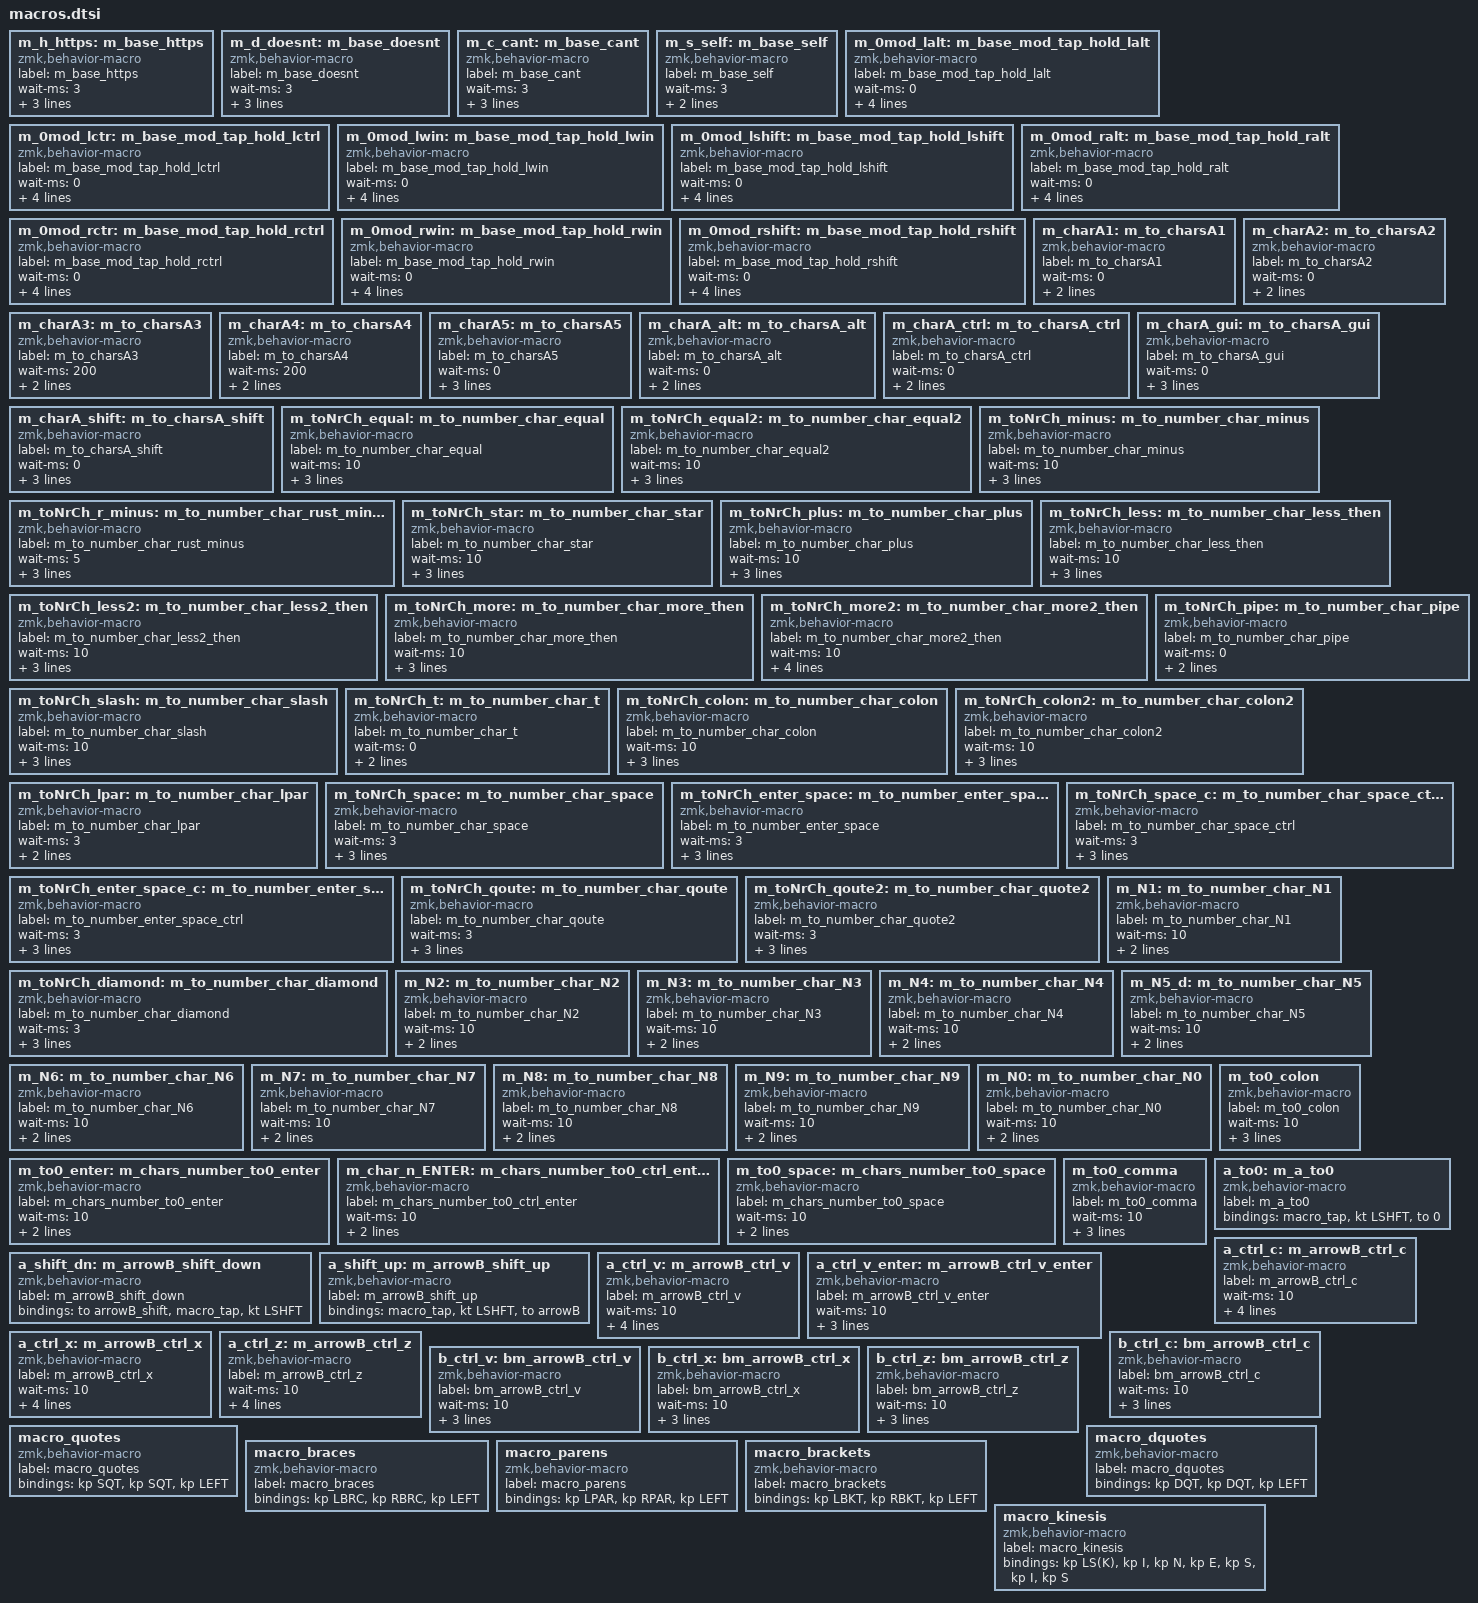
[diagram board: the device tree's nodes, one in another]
// --------------------------------------------------------


// --------------------------------------------------------

// string: 'https://'
m_h_https: m_base_https  {
            label = "m_base_https";
            compatible = "zmk,behavior-macro";
            #binding-cells = <0>;
            wait-ms = <3>;
            tap-ms = <8>;
            bindings
              = <&macro_tap &kp H &kp T &kp T &kp P &kp S &kp COLON &kp SLASH &kp SLASH>;
      };

m_d_doesnt: m_base_doesnt  {
            label = "m_base_doesnt";
            compatible = "zmk,behavior-macro";
            #binding-cells = <0>;
            wait-ms = <3>;
            tap-ms = <8>;
            bindings
              = <&macro_tap &kp D &kp O &kp E &kp S &kp N &kp SINGLE_QUOTE &kp T>;
      };

m_c_cant: m_base_cant  {
            label = "m_base_cant";
            compatible = "zmk,behavior-macro";
            #binding-cells = <0>;
            wait-ms = <3>;
            tap-ms = <8>;
            bindings
              = <&macro_tap &kp C &kp A &kp N &kp SINGLE_QUOTE &kp T>;
      };

// self
m_s_self: m_base_self  {
            label = "m_base_self";
            compatible = "zmk,behavior-macro";
            #binding-cells = <0>;
            wait-ms = <3>;
            tap-ms = <8>;
            bindings
              = <&macro_tap &kp S &kp E &kp L &kp F>;
              //= <&macro_tap &kp S &kp E &kp L &kp F &kp DOT>;
      };


// --------------------------------------------------------

m_0mod_lalt: m_base_mod_tap_hold_lalt  {
            label = "m_base_mod_tap_hold_lalt";
            compatible = "zmk,behavior-macro";
            #binding-cells = <0>;
            wait-ms = <0>;
            tap-ms = <0>;
            bindings
              = <&macro_press &mo base_mod &kp LALT>
              , <&macro_pause_for_release>
              , <&macro_release &mo base_mod &kp LALT>;
      };

m_0mod_lctr: m_base_mod_tap_hold_lctrl  {
            label = "m_base_mod_tap_hold_lctrl";
            compatible = "zmk,behavior-macro";
            #binding-cells = <0>;
            wait-ms = <0>;
            tap-ms = <0>;
            bindings
              = <&macro_press &mo base_mod &kp LCTRL>
              , <&macro_pause_for_release>
              , <&macro_release &mo base_mod &kp LCTRL>;
      };

m_0mod_lwin: m_base_mod_tap_hold_lwin  {
            label = "m_base_mod_tap_hold_lwin";
            compatible = "zmk,behavior-macro";
            #binding-cells = <0>;
            wait-ms = <0>;
            tap-ms = <0>;
            bindings
              = <&macro_press &mo base_mod &kp LWIN>
              , <&macro_pause_for_release>
              , <&macro_release &mo base_mod &kp LWIN>;
      };

m_0mod_lshift: m_base_mod_tap_hold_lshift  {
            label = "m_base_mod_tap_hold_lshift";
            compatible = "zmk,behavior-macro";
            #binding-cells = <0>;
            wait-ms = <0>;
            tap-ms = <0>;
            bindings
              = <&macro_press &mo base_mod &kp LSHIFT>
              , <&macro_pause_for_release>
              , <&macro_release &mo base_mod &kp LSHIFT>;
      };

// ------- 

m_0mod_ralt: m_base_mod_tap_hold_ralt  {
            label = "m_base_mod_tap_hold_ralt";
            compatible = "zmk,behavior-macro";
            #binding-cells = <0>;
            wait-ms = <0>;
            tap-ms = <0>;
            bindings
              = <&macro_press &mo base_mod &kp RALT>
              , <&macro_pause_for_release>
              , <&macro_release &mo base_mod &kp RALT>;
      };

m_0mod_rctr: m_base_mod_tap_hold_rctrl  {
            label = "m_base_mod_tap_hold_rctrl";
            compatible = "zmk,behavior-macro";
            #binding-cells = <0>;
            wait-ms = <0>;
            tap-ms = <0>;
            bindings
              = <&macro_press &mo base_mod &kp RCTRL>
              , <&macro_pause_for_release>
              , <&macro_release &mo base_mod &kp RCTRL>;
      };

m_0mod_rwin: m_base_mod_tap_hold_rwin  {
            label = "m_base_mod_tap_hold_rwin";
            compatible = "zmk,behavior-macro";
            #binding-cells = <0>;
            wait-ms = <0>;
            tap-ms = <0>;
            bindings
              = <&macro_press &mo base_mod &kp RWIN>
              , <&macro_pause_for_release>
              , <&macro_release &mo base_mod &kp RWIN>;
      };

m_0mod_rshift: m_base_mod_tap_hold_rshift  {
            label = "m_base_mod_tap_hold_rshift";
            compatible = "zmk,behavior-macro";
            #binding-cells = <0>;
            wait-ms = <0>;
            tap-ms = <0>;
            bindings
              = <&macro_press &mo base_mod &kp RSHIFT>
              , <&macro_pause_for_release>
              , <&macro_release &mo base_mod &kp RSHIFT>;
      };


// --------------------------------------------------------

m_charA1: m_to_charsA1 {
            label = "m_to_charsA1";
            compatible = "zmk,behavior-macro";
            #binding-cells = <0>;
            wait-ms = <0>;
            tap-ms = <0>;
            bindings
                = <&macro_tap &skq LALT>
                ;
      };

m_charA2: m_to_charsA2 {
            label = "m_to_charsA2";
            compatible = "zmk,behavior-macro";
            #binding-cells = <0>;
            wait-ms = <0>;
            tap-ms = <0>;
            bindings
                = <&macro_tap &sk LALT>
                ;
      };

m_charA3: m_to_charsA3 {
            label = "m_to_charsA3";
            compatible = "zmk,behavior-macro";
            #binding-cells = <0>;
            wait-ms = <200>;
            tap-ms = <200>;       
            bindings
                = <&macro_tap &sk LALT>
                ;
      };

m_charA4: m_to_charsA4 {
            label = "m_to_charsA4";
            compatible = "zmk,behavior-macro";
            #binding-cells = <0>;
            wait-ms = <200>;
            tap-ms = <200>;
            bindings
                = <&macro_tap &skq LALT>
                ;
      };

m_charA5: m_to_charsA5 {
            label = "m_to_charsA5";
            compatible = "zmk,behavior-macro";
            #binding-cells = <0>;
            wait-ms = <0>;
            tap-ms = <0>;
            bindings
                = <&macro_tap &sl1 charsA &sk1 LALT &sl1 charsA>
                ;
      };
                //= <&macro_tap &sk1 LALT &sl1 charsA>
                //, <&macro_tap &sl1 charsA>

m_charA_alt: m_to_charsA_alt {
            label = "m_to_charsA_alt";
            compatible = "zmk,behavior-macro";
            #binding-cells = <0>;
            wait-ms = <0>;
            tap-ms = <0>;
            bindings
                = <&to 0>
                , <&macro_tap &skq LALT>
                , <&sl charsA>
                ;
      };

m_charA_ctrl: m_to_charsA_ctrl {
            label = "m_to_charsA_ctrl";
            compatible = "zmk,behavior-macro";
            #binding-cells = <0>;
            wait-ms = <0>;
            tap-ms = <0>;
            bindings
                = <&macro_tap &sk LCTRL>
                , <&sl charsA>
                ;
      };

m_charA_gui: m_to_charsA_gui {
            label = "m_to_charsA_gui";
            compatible = "zmk,behavior-macro";
            #binding-cells = <0>;
            wait-ms = <0>;
            tap-ms = <0>;
            bindings
                = <&macro_press &sk LGUI>
                , <&to charsA>
                , <&macro_release &sk LGUI>
                , <&to 0>
                ;
      };

m_charA_shift: m_to_charsA_shift {
            label = "m_to_charsA_shift";
            compatible = "zmk,behavior-macro";
            #binding-cells = <0>;
            wait-ms = <0>;
            tap-ms = <0>;
            bindings
                = <&macro_press &sk LSHIFT>
                , <&sl charsA>
                , <&macro_release &sk LSHIFT>
                ;
      };


//                = <&macro_tap &kt LSHFT> 
//                , <&to arrowB>
//                , <&macro_press &kp LCTRL>
//                , <&macro_tap &kp C>
//                , <&macro_release &kp LCTRL>


// --------------------------------------------------------

    m_toNrCh_equal: m_to_number_char_equal {
            label = "m_to_number_char_equal";
            compatible = "zmk,behavior-macro";
            #binding-cells = <0>;
            wait-ms = <10>;
            tap-ms = <10>;
            bindings
                = <&to chars_number>
                , <&macro_tap &kp SPACE &kp EQUAL &kp SPACE>
                ;
      };

    m_toNrCh_equal2: m_to_number_char_equal2 {
            label = "m_to_number_char_equal2";
            compatible = "zmk,behavior-macro";
            #binding-cells = <0>;
            wait-ms = <10>;
            tap-ms = <10>;
            bindings
                = <&to chars_number>
                , <&macro_tap &kp SPACE &kp EQUAL &kp EQUAL &kp SPACE>
                ;
      };

    m_toNrCh_minus: m_to_number_char_minus {
            label = "m_to_number_char_minus";
            compatible = "zmk,behavior-macro";
            #binding-cells = <0>;
            wait-ms = <10>;
            tap-ms = <10>;
            bindings
                = <&to chars_number>
                , <&macro_tap &kp SPACE &kp MINUS &kp SPACE>
                ;
      };

//used in Rust at the end of function
// fn name(args) -> String

    m_toNrCh_r_minus: m_to_number_char_rust_minus {
            label = "m_to_number_char_rust_minus";
            compatible = "zmk,behavior-macro";
            #binding-cells = <0>;
            wait-ms = <5>;
            tap-ms = <10>;
            bindings
                = <&macro_tap &kp END &kp SPACE &kp MINUS &kp GREATER_THAN &kp SPACE>
                ;
      };

    m_toNrCh_star: m_to_number_char_star {
            label = "m_to_number_char_star";
            compatible = "zmk,behavior-macro";
            #binding-cells = <0>;
            wait-ms = <10>;
            tap-ms = <10>;
            bindings
                = <&to chars_number>
                , <&macro_tap &kp SPACE &kp STAR &kp SPACE>
                ;
      };

   m_toNrCh_plus: m_to_number_char_plus {
            label = "m_to_number_char_plus";
            compatible = "zmk,behavior-macro";
            #binding-cells = <0>;
            wait-ms = <10>;
            tap-ms = <10>;
            bindings
                = <&to chars_number>
                , <&macro_tap &kp SPACE &kp PLUS &kp SPACE>
                ;
      };

  m_toNrCh_less: m_to_number_char_less_then {
            label = "m_to_number_char_less_then";
            compatible = "zmk,behavior-macro";
            #binding-cells = <0>;
            wait-ms = <10>;
            tap-ms = <10>;
            bindings
                = <&to chars_number>
                , <&macro_tap &kp SPACE &kp LESS_THAN &kp SPACE>
                ;
      }; 

  m_toNrCh_less2: m_to_number_char_less2_then {
            label = "m_to_number_char_less2_then";
            compatible = "zmk,behavior-macro";
            #binding-cells = <0>;
            wait-ms = <10>;
            tap-ms = <10>;
            bindings
                = <&to chars_number>
                , <&macro_tap &kp SPACE &kp LESS_THAN &kp EQUAL &kp SPACE>
                ;
      }; 

    m_toNrCh_more: m_to_number_char_more_then {
            label = "m_to_number_char_more_then";
            compatible = "zmk,behavior-macro";
            #binding-cells = <0>;
            wait-ms = <10>;
            tap-ms = <10>;
            bindings
                = <&to chars_number>
                , <&macro_tap &kp SPACE &kp GREATER_THAN &kp SPACE>
                ;
      }; 

    m_toNrCh_more2: m_to_number_char_more2_then {
            label = "m_to_number_char_more2_then";
            compatible = "zmk,behavior-macro";
            #binding-cells = <0>;
            wait-ms = <10>;
            tap-ms = <10>;
            bindings
                = <&to chars_number>
                , <&macro_tap &kp SPACE &kp GREATER_THAN &kp EQUAL &kp SPACE>
                ;
      }; 


    m_toNrCh_slash: m_to_number_char_slash {
            label = "m_to_number_char_slash";
            compatible = "zmk,behavior-macro";
            #binding-cells = <0>;
            wait-ms = <10>;
            tap-ms = <10>;
            bindings
                = <&to chars_number>
                , <&macro_tap &kp SPACE &kp SLASH &kp SPACE>
                ;
      }; 

    m_toNrCh_pipe: m_to_number_char_pipe {
            label = "m_to_number_char_pipe";
            compatible = "zmk,behavior-macro";
            #binding-cells = <0>;
            wait-ms = <0>;
            tap-ms = <10>;
            bindings
                = <&macro_tap &kp BACKSLASH &kp N>
                ;
      }; 

    m_toNrCh_t: m_to_number_char_t {
            label = "m_to_number_char_t";
            compatible = "zmk,behavior-macro";
            #binding-cells = <0>;
            wait-ms = <0>;
            tap-ms = <10>;
            bindings
                = <&macro_tap &kp BACKSLASH &kp T>
                ;
      }; 



//helps in "c" language to type the semicolon and move to new line
//often currsor is in a middle of some string, example: myarray[1|]

m_toNrCh_colon: m_to_number_char_colon {
            label = "m_to_number_char_colon";
            compatible = "zmk,behavior-macro";
            #binding-cells = <0>;
            wait-ms = <10>;
            tap-ms = <10>;
            bindings
                = <&to DEFAULT>
                , <&macro_tap &kp END &kp SEMI &kp ENTER>
                ;
      }; 


m_toNrCh_colon2: m_to_number_char_colon2 {
            label = "m_to_number_char_colon2";
            compatible = "zmk,behavior-macro";
            #binding-cells = <0>;
            wait-ms = <10>;
            tap-ms = <10>;
            bindings
                = <&to DEFAULT>
                , <&macro_tap &kp END &kp SEMI &kp DOWN>
                ;
      }; 


// in rust or other languages type: '().' vvv

m_toNrCh_lpar: m_to_number_char_lpar {
            label = "m_to_number_char_lpar";
            compatible = "zmk,behavior-macro";
            #binding-cells = <0>;
            wait-ms = <3>;
            tap-ms = <8>;
            bindings
                = <&macro_tap &kp LPAR &kp RPAR &kp DOT>
                ;
      }; 


// used to move the currsor to the end of line and press space
// example: "text|" -> "text" |
m_toNrCh_space: m_to_number_char_space {
            label = "m_to_number_char_space";
            compatible = "zmk,behavior-macro";
            #binding-cells = <0>;
            wait-ms = <3>;
            tap-ms = <8>;
            bindings
                = <&to DEFAULT>
                , <&macro_tap &kp LA(RIGHT)>
                , <&macro_tap &kp SPACE>
                ;
      }; 

// used to move the currsor to the end of line and press space
// example: "text|" -> "text" |
m_toNrCh_enter_space: m_to_number_enter_space {
            label = "m_to_number_enter_space";
            compatible = "zmk,behavior-macro";
            #binding-cells = <0>;
            wait-ms = <3>;
            tap-ms = <8>;
            bindings
                = <&to chars_number>
                , <&macro_tap &kp LA(RIGHT)>
                , <&macro_tap &kp SPACE>
                ;
      }; 

// used to move the currsor to the end of line and press space
// example: "text|" -> "text" |
m_toNrCh_space_c: m_to_number_char_space_ctrl {
            label = "m_to_number_char_space_ctrl";
            compatible = "zmk,behavior-macro";
            #binding-cells = <0>;
            wait-ms = <3>;
            tap-ms = <8>;
            bindings
                = <&to DEFAULT>
                , <&macro_tap &kp LC(RIGHT)>
                , <&macro_tap &kp SPACE>
                ;
      }; 

// used to move the currsor to the end of line and press space
// example: "text|" -> "text" |
m_toNrCh_enter_space_c: m_to_number_enter_space_ctrl {
            label = "m_to_number_enter_space_ctrl";
            compatible = "zmk,behavior-macro";
            #binding-cells = <0>;
            wait-ms = <3>;
            tap-ms = <8>;
            bindings
                = <&to chars_number>
                , <&macro_tap &kp LC(RIGHT)>
                , <&macro_tap &kp SPACE>
                ;
      }; 


m_toNrCh_qoute: m_to_number_char_qoute {
            label = "m_to_number_char_qoute";
            compatible = "zmk,behavior-macro";
            #binding-cells = <0>;
            wait-ms = <3>;
            tap-ms = <8>;
            bindings
                = <&macro_tap &kp SINGLE_QUOTE &kp SINGLE_QUOTE &kp SINGLE_QUOTE>
                ;
      }; 

m_toNrCh_qoute2: m_to_number_char_quote2 {
            label = "m_to_number_char_quote2";
            compatible = "zmk,behavior-macro";
            #binding-cells = <0>;
            wait-ms = <3>;
            tap-ms = <8>;
            bindings
                = <&macro_tap &kp DOUBLE_QUOTES &kp DOUBLE_QUOTES &kp DOUBLE_QUOTES>
                ;
      }; 


// allows you type: <numbers+>
// example: <1>

m_toNrCh_diamond: m_to_number_char_diamond {
            label = "m_to_number_char_diamond";
            compatible = "zmk,behavior-macro";
            #binding-cells = <0>;
            wait-ms = <3>;
            tap-ms = <8>;
            bindings
                = <&to chars_number>
                , <&macro_tap &kp LESS_THAN &kp GREATER_THAN &kp LEFT>
                ;
      }; 


    m_N1: m_to_number_char_N1 {
            label = "m_to_number_char_N1";
            compatible = "zmk,behavior-macro";
            #binding-cells = <0>;
            wait-ms = <10>;
            tap-ms = <10>;
            bindings
                = <&to chars_number>
                , <&macro_tap &kp N1>
                ;
      }; 

    m_N2: m_to_number_char_N2 {
            label = "m_to_number_char_N2";
            compatible = "zmk,behavior-macro";
            #binding-cells = <0>;
            wait-ms = <10>;
            tap-ms = <10>;
            bindings
                = <&to chars_number>
                , <&macro_tap &kp N2>
                ;
      }; 

    m_N3: m_to_number_char_N3 {
            label = "m_to_number_char_N3";
            compatible = "zmk,behavior-macro";
            #binding-cells = <0>;
            wait-ms = <10>;
            tap-ms = <10>;
            bindings
                = <&to chars_number>
                , <&macro_tap &kp N3>
                ;
      }; 

    m_N4: m_to_number_char_N4 {
            label = "m_to_number_char_N4";
            compatible = "zmk,behavior-macro";
            #binding-cells = <0>;
            wait-ms = <10>;
            tap-ms = <10>;
            bindings
                = <&to chars_number>
                , <&macro_tap &kp N4>
                ;
      }; 

    m_N5_d: m_to_number_char_N5 {
            label = "m_to_number_char_N5";
            compatible = "zmk,behavior-macro";
            #binding-cells = <0>;
            wait-ms = <10>;
            tap-ms = <10>;
            bindings
                = <&kp BACKSLASH>
                , <&kp D>
                ;
      }; 

    m_N6: m_to_number_char_N6 {
            label = "m_to_number_char_N6";
            compatible = "zmk,behavior-macro";
            #binding-cells = <0>;
            wait-ms = <10>;
            tap-ms = <10>;
            bindings
                = <&mo chars_number>
                , <&macro_tap &kp N6>
                ;
      }; 

    m_N7: m_to_number_char_N7 {
            label = "m_to_number_char_N7";
            compatible = "zmk,behavior-macro";
            #binding-cells = <0>;
            wait-ms = <10>;
            tap-ms = <10>;
            bindings
                = <&to chars_number>
                , <&macro_tap &kp N7>
                ;
      }; 

    m_N8: m_to_number_char_N8 {
            label = "m_to_number_char_N8";
            compatible = "zmk,behavior-macro";
            #binding-cells = <0>;
            wait-ms = <10>;
            tap-ms = <10>;
            bindings
                = <&to chars_number>
                , <&macro_tap &kp N8>
                ;
      }; 

    m_N9: m_to_number_char_N9 {
            label = "m_to_number_char_N9";
            compatible = "zmk,behavior-macro";
            #binding-cells = <0>;
            wait-ms = <10>;
            tap-ms = <10>;
            bindings
                = <&to chars_number>
                , <&macro_tap &kp N9>
                ;
      }; 

    m_N0: m_to_number_char_N0 {
            label = "m_to_number_char_N0";
            compatible = "zmk,behavior-macro";
            #binding-cells = <0>;
            wait-ms = <10>;
            tap-ms = <10>;
            bindings
                = <&to chars_number>
                , <&macro_tap &kp N0>
                ;
      }; 


//    m_toNrCh: m_to_number_char {
//            label = "m_to_number_char";
//            compatible = "zmk,behavior-macro";
//            #binding-cells = <0>;
//            wait-ms = <10>;
//            tap-ms = <10>;
//            bindings
//              = <&macro_press &mo_ChNr_tog chars_number_m A>
//              , <&macro_tap &kp SPACE>
//              , <&macro_pause_for_release>
//              , <&macro_release &mo_ChNr_tog chars_number_m A>
//              ;
//      };


// --------------------------------------------------------

    m_to0_enter: m_chars_number_to0_enter {
            label = "m_chars_number_to0_enter";
            compatible = "zmk,behavior-macro";
            #binding-cells = <0>;
            wait-ms = <10>;
            tap-ms = <10>;
            bindings
                = <&to 0>
                , <&macro_tap &kp ENTER>
                ;
      };

      m_char_n_ENTER: m_chars_number_to0_ctrl_enter {
            label = "m_chars_number_to0_ctrl_enter";
            compatible = "zmk,behavior-macro";
            #binding-cells = <0>;
            wait-ms = <10>;
            tap-ms = <10>;
            bindings
                = <&to 0>
                , <&macro_tap &kp LC(ENTER)>
                ;
      };

      m_to0_space: m_chars_number_to0_space {
            label = "m_chars_number_to0_space";
            compatible = "zmk,behavior-macro";
            #binding-cells = <0>;
            wait-ms = <10>;
            tap-ms = <10>;
            bindings
                = <&to 0>
                , <&macro_tap &kp SPACE>
                ;
      };

  m_to0_colon: m_to0_colon {
            label = "m_to0_colon";
            compatible = "zmk,behavior-macro";
            #binding-cells = <0>;
            wait-ms = <10>;
            tap-ms = <10>;
            bindings
                = <&to DEFAULT>
                , <&macro_tap &kp END &kp COLON &kp ENTER>
                ;
      }; 


  m_to0_comma: m_to0_comma {
            label = "m_to0_comma";
            compatible = "zmk,behavior-macro";
            #binding-cells = <0>;
            wait-ms = <10>;
            tap-ms = <10>;
            bindings
                = <&to DEFAULT>
                , <&macro_tap &kp END &kp COMMA &kp ENTER>
                ;
      }; 

// --------------------------------------------------------

   a_shift_dn: m_arrowB_shift_down {
            label = "m_arrowB_shift_down";
            compatible = "zmk,behavior-macro";
            #binding-cells = <0>;
            bindings
                = <&to arrowB_shift>
                , <&macro_tap &kt LSHFT>
                ;
        };

  a_shift_up: m_arrowB_shift_up {
            label = "m_arrowB_shift_up";
            compatible = "zmk,behavior-macro";
            #binding-cells = <0>;
            bindings
                = <&macro_tap &kt LSHFT>
                , <&to arrowB>
                ;
        };

    a_to0: m_a_to0 {
            label = "m_a_to0";
            compatible = "zmk,behavior-macro";
            #binding-cells = <0>;
            bindings
                = <&macro_tap &kt LSHFT>
                , <&to 0>
                ;
        };
// --------------------------------------------------------

    a_ctrl_c: m_arrowB_ctrl_c {
            label = "m_arrowB_ctrl_c";
            compatible = "zmk,behavior-macro";
            #binding-cells = <0>;
            wait-ms = <10>;
            tap-ms = <10>;
            bindings
                = <&macro_tap &kt LSHFT> 
                , <&to arrowB>
                , <&macro_press &kp LCTRL>
                , <&macro_tap &kp C>
                , <&macro_release &kp LCTRL>
                ;
      };

   a_ctrl_v: m_arrowB_ctrl_v {
            label = "m_arrowB_ctrl_v";
            compatible = "zmk,behavior-macro";
            #binding-cells = <0>;
            wait-ms = <10>;
            tap-ms = <10>;
            bindings
                = <&macro_tap &kt LSHFT> 
                , <&to arrowB>
                , <&macro_press &kp LCTRL>
                , <&macro_tap &kp V>
                , <&macro_release &kp LCTRL>
                ;
      };

       a_ctrl_v_enter: m_arrowB_ctrl_v_enter {
            label = "m_arrowB_ctrl_v_enter";
            compatible = "zmk,behavior-macro";
            #binding-cells = <0>;
            wait-ms = <10>;
            tap-ms = <10>;
            bindings
                = <&macro_tap &kp LC(V)>
                , <&macro_tap &kp ENTER>
                ;
      };

     a_ctrl_x: m_arrowB_ctrl_x {
            label = "m_arrowB_ctrl_x";
            compatible = "zmk,behavior-macro";
            #binding-cells = <0>; 
            wait-ms = <10>;
            tap-ms = <10>;
            bindings
                = <&macro_tap &kt LSHFT> 
                , <&to arrowB>
                , <&macro_press &kp LCTRL>
                , <&macro_tap &kp X>
                , <&macro_release &kp LCTRL>
                ;
      };

     a_ctrl_z: m_arrowB_ctrl_z {
            label = "m_arrowB_ctrl_z";
            compatible = "zmk,behavior-macro";
            #binding-cells = <0>;
            wait-ms = <10>;
            tap-ms = <10>;
            bindings
                = <&macro_tap &kt LSHFT> 
                , <&to arrowB>
                , <&macro_press &kp LCTRL>
                , <&macro_tap &kp Z>
                , <&macro_release &kp LCTRL>
                ;
      };
// --------------------------------------------------------
    b_ctrl_c: bm_arrowB_ctrl_c {
            label = "bm_arrowB_ctrl_c";
            compatible = "zmk,behavior-macro";
            #binding-cells = <0>;
            wait-ms = <10>;
            tap-ms = <10>;
            bindings
                = <&to arrowB>
                , <&macro_press &kp LCTRL>
                , <&macro_tap &kp C>
                , <&macro_release &kp LCTRL>
                ;
      };

   b_ctrl_v: bm_arrowB_ctrl_v {
            label = "bm_arrowB_ctrl_v";
            compatible = "zmk,behavior-macro";
            #binding-cells = <0>;
            wait-ms = <10>;
            tap-ms = <10>;
            bindings
                = <&to arrowB>
                , <&macro_press &kp LCTRL>
                , <&macro_tap &kp V>
                , <&macro_release &kp LCTRL>
                ;
      };

     b_ctrl_x: bm_arrowB_ctrl_x {
            label = "bm_arrowB_ctrl_x";
            compatible = "zmk,behavior-macro";
            #binding-cells = <0>; 
            wait-ms = <10>;
            tap-ms = <10>;
            bindings
                = <&to arrowB>
                , <&macro_press &kp LCTRL>
                , <&macro_tap &kp X>
                , <&macro_release &kp LCTRL>
                ;
      };

     b_ctrl_z: bm_arrowB_ctrl_z {
            label = "bm_arrowB_ctrl_z";
            compatible = "zmk,behavior-macro";
            #binding-cells = <0>;
            wait-ms = <10>;
            tap-ms = <10>;
            bindings
                = <&to arrowB>
                , <&macro_press &kp LCTRL>
                , <&macro_tap &kp Z>
                , <&macro_release &kp LCTRL>
                ;
      };
// --------------------------------------------------------

  macro_quotes: macro_quotes {
    compatible = "zmk,behavior-macro";
    label = "macro_quotes";
    #binding-cells = <0>;
    bindings = <&kp SQT>, <&kp SQT>, <&kp LEFT>;
  };
  macro_dquotes: macro_dquotes {
    compatible = "zmk,behavior-macro";
    label = "macro_dquotes";
    #binding-cells = <0>;
    bindings = <&kp DQT>, <&kp DQT>, <&kp LEFT>;
  };
  macro_braces: macro_braces {
    compatible = "zmk,behavior-macro";
    label = "macro_braces";
    #binding-cells = <0>;
    bindings = <&kp LBRC>, <&kp RBRC>, <&kp LEFT>;
  };
  macro_parens: macro_parens {
    compatible = "zmk,behavior-macro";
    label = "macro_parens";
    #binding-cells = <0>;
    bindings = <&kp LPAR>, <&kp RPAR>, <&kp LEFT>;
  };
  macro_brackets: macro_brackets {
    compatible = "zmk,behavior-macro";
    label = "macro_brackets";
    #binding-cells = <0>;
    bindings = <&kp LBKT>, <&kp RBKT>, <&kp LEFT>;
  };
  macro_kinesis: macro_kinesis {
    compatible = "zmk,behavior-macro";
    label = "macro_kinesis";
    #binding-cells = <0>;
    bindings = <&kp LS(K)>, <&kp I>, <&kp N>, <&kp E>, <&kp S>, <&kp I>, <&kp S>;
  };
